VERSION ""

NS_ :

BS_:

BU_: XXX

BO_ 390 RPM: 8 XXX
 SG_ _RPM : 7|16@0+ (0.1,0) [0|65535] "" XXX

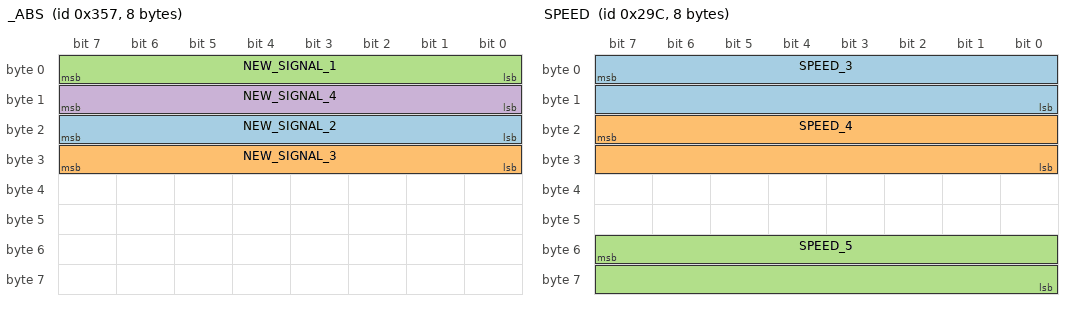
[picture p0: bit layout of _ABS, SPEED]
BO_ 855 _ABS: 8 XXX
 SG_ NEW_SIGNAL_2 : 23|8@0+ (1,0) [0|65535] "" XXX
 SG_ NEW_SIGNAL_3 : 31|8@0+ (1,0) [0|255] "" XXX
 SG_ NEW_SIGNAL_1 : 7|8@0+ (1,0) [0|65535] "" XXX
 SG_ NEW_SIGNAL_4 : 15|8@0+ (1,0) [0|255] "" XXX

BO_ 666 SPEED: 8 XXX
 SG_ SPEED : 7|16@0+ (0.005,0) [0|65535] "" XXX
 SG_ SPEED_2 : 23|16@0+ (0.005,0) [0|65535] "" XXX

BO_ 852 SPEED2: 8 XXX
 SG_ SPEED : 7|16@0+ (0.01,0) [0|65535] "" XXX

BO_ 668 SPEED: 8 XXX
 SG_ SPEED_3 : 7|16@0+ (0.005,0) [0|65535] "" XXX
 SG_ SPEED_4 : 23|16@0+ (0.005,0) [0|65535] "" XXX
 SG_ SPEED_5 : 55|16@0+ (0.01,0) [0|65535] "" XXX

BO_ 535 TBD: 8 XXX
 SG_ _SPEED : 31|16@0+ (1,0) [0|255] "" XXX
 SG_ _TBD : 47|8@0+ (1,0) [0|65535] "" XXX

BO_ 302 STEERING: 8 XXX
 SG_ STEERING : 31|16@0+ (1,0) [0|255] "" XXX

BO_ 1642 NEW_MSG_1: 8 XXX
 SG_ NEW_SIGNAL_1 : 23|16@0+ (1,0) [0|255] "" XXX
 SG_ NEW_SIGNAL_2 : 39|16@0+ (1,0) [0|65535] "" XXX
